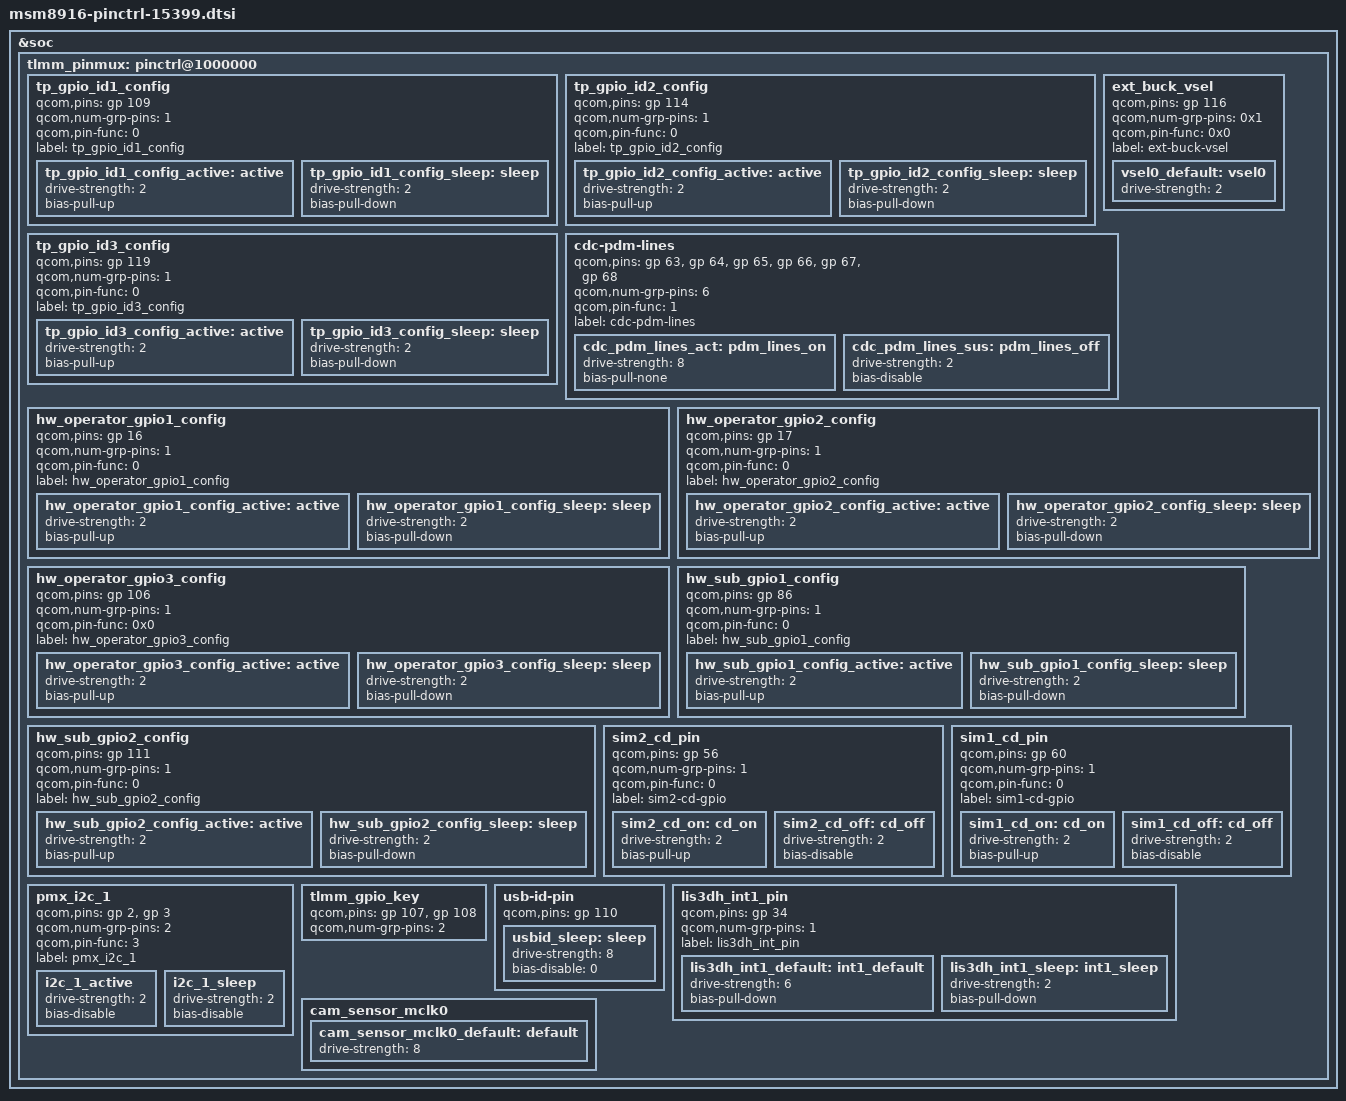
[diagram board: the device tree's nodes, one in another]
/* Copyright (c) 2020, The Linux Foundation. All rights reserved.
*  Copyright (c) 2020, the_shahnawaz_sheikh (sheikhshahnawaz41299).
*
* This program is free software; you can redistribute it and/or modify
* it under the terms of the GNU General Public License version 2 and
* only version 2 as published by the Free Software Foundation.
*
* This program is distributed in the hope that it will be useful,
* but WITHOUT ANY WARRANTY; without even the implied warranty of
* MERCHANTABILITY or FITNESS FOR A PARTICULAR PURPOSE.  See the
* GNU General Public License for more details.
*/

#include "../msm8916-pinctrl.dtsi"

&soc {
	tlmm_pinmux: pinctrl@1000000 {
	
	    /delete-node/ tps61310_pins;
		/delete-node/ spi2_cs2_active;
		/delete-node/ spi2_cs2_suspend;
		/delete-node/ spi2_active;
		/delete-node/ spi2_suspend;
		/delete-node/ ice40-spi-usb-pins;
		
		tp_gpio_id1_config {
			qcom,pins = <&gp 109>;
			qcom,num-grp-pins = <1>;
			qcom,pin-func = <0>;
			label = "tp_gpio_id1_config";

			tp_gpio_id1_config_active: active {
				drive-strength = <2>;
				bias-pull-up;
			};

			tp_gpio_id1_config_sleep: sleep {
				drive-strength = <2>;
				bias-pull-down;
			};
		};

		tp_gpio_id2_config {
			qcom,pins = <&gp 114>;
			qcom,num-grp-pins = <1>;
			qcom,pin-func = <0>;
			label = "tp_gpio_id2_config";

			tp_gpio_id2_config_active: active {
				drive-strength = <2>;
				bias-pull-up;
			};

			tp_gpio_id2_config_sleep: sleep {
				drive-strength = <2>;
				bias-pull-down;
			};
		};
		
		tp_gpio_id3_config { 
			qcom,pins = <&gp 119>;
			qcom,num-grp-pins = <1>;
			qcom,pin-func = <0>;
			label = "tp_gpio_id3_config";

			tp_gpio_id3_config_active:	active {
					drive-strength = <2>;
					bias-pull-up;
			};

			tp_gpio_id3_config_sleep:	sleep {
					drive-strength = <2>;
					bias-pull-down;
			};
		};
		
		ext_buck_vsel { 
			qcom,pins = <&gp 116>;
			qcom,num-grp-pins = <0x1>;
			qcom,pin-func = <0x0>;
			label = "ext-buck-vsel";

			vsel0_default: vsel0 {
					drive-strength = <2>;
			};
		};
		
		cdc-pdm-lines {
			 qcom,pins = <&gp 63>, <&gp 64>, <&gp 65>,
					<&gp 66>, <&gp 67>, <&gp 68>;
			 qcom,num-grp-pins = <6>;
			 qcom,pin-func = <1>;
			 label = "cdc-pdm-lines";
			 
			 cdc_pdm_lines_act: pdm_lines_on {
				  drive-strength = <8>;
				  bias-pull-none;
			 };
			  
			 cdc_pdm_lines_sus: pdm_lines_off {
				  drive-strength = <2>;
				 /delete-property/ bias-pull-down; 
				 bias-disable;  
			 };
	    };
		
		hw_operator_gpio1_config { 
				qcom,pins = <&gp 16>;
				qcom,num-grp-pins = <1>;
				qcom,pin-func = <0>;
				label = "hw_operator_gpio1_config";

			hw_operator_gpio1_config_active: active {
					drive-strength = <2>;
					bias-pull-up;
				};

			hw_operator_gpio1_config_sleep:	sleep {
					drive-strength = <2>;
					bias-pull-down;
				};
		};

		hw_operator_gpio2_config { 
				qcom,pins = <&gp 17>;
				qcom,num-grp-pins = <1>;
				qcom,pin-func = <0>;
				label = "hw_operator_gpio2_config";

			hw_operator_gpio2_config_active:	active {
					drive-strength = <2>;
					bias-pull-up;
				};

			hw_operator_gpio2_config_sleep:	sleep {
					drive-strength = <2>;
					bias-pull-down;
				};
		};

		hw_operator_gpio3_config { 
				qcom,pins = <&gp 106>;
				qcom,num-grp-pins = <1>;
				qcom,pin-func = <0x0>;
				label = "hw_operator_gpio3_config";

			hw_operator_gpio3_config_active:	active {
					drive-strength = <2>;
					bias-pull-up;
				};

			hw_operator_gpio3_config_sleep:	sleep {
					drive-strength = <2>;
					bias-pull-down;
				};
		};


		hw_sub_gpio1_config {
			qcom,pins = <&gp 86>;
			qcom,num-grp-pins = <1>;
			qcom,pin-func = <0>;
			label = "hw_sub_gpio1_config";

			hw_sub_gpio1_config_active: active {
				drive-strength = <2>;
				bias-pull-up;
			};

			hw_sub_gpio1_config_sleep: sleep {
				drive-strength = <2>;
				bias-pull-down;
			};
		};

		hw_sub_gpio2_config {
			qcom,pins = <&gp 111>;
			qcom,num-grp-pins = <1>;
			qcom,pin-func = <0>;
			label = "hw_sub_gpio2_config";

			hw_sub_gpio2_config_active: active {
				drive-strength = <2>;
				bias-pull-up;
			};

			hw_sub_gpio2_config_sleep: sleep {
				drive-strength = <2>;
				bias-pull-down;
			};
		};

		sim2_cd_pin {
			qcom,pins = <&gp 56>;
			qcom,num-grp-pins = <1>;
			qcom,pin-func = <0>;
			label = "sim2-cd-gpio";

			sim2_cd_on: cd_on {
				drive-strength = <2>;
				bias-pull-up;
			};

			sim2_cd_off: cd_off {
				drive-strength = <2>;
				bias-disable;
			};
		};

		sim1_cd_pin {
			qcom,pins = <&gp 60>;
			qcom,num-grp-pins = <1>;
			qcom,pin-func = <0>;
			label = "sim1-cd-gpio";

			sim1_cd_on: cd_on {
				drive-strength = <2>;
				bias-pull-up;
			};

			sim1_cd_off: cd_off {
				drive-strength = <2>;
				bias-disable;
			};
		};

		pmx_i2c_1 {
			qcom,pins = <&gp 2>, <&gp 3>;
			qcom,num-grp-pins = <2>;
			qcom,pin-func = <3>;
			label = "pmx_i2c_1";

			i2c_1_active: i2c_1_active {
				drive-strength = <2>;
				bias-disable;
			};

			i2c_1_sleep: i2c_1_sleep {
				drive-strength = <2>;
				bias-disable;
			};
		};
		
		
		tlmm_gpio_key {
              qcom,pins = <&gp 107> , <&gp 108>;
              qcom,num-grp-pins = <2>;
         };

		usb-id-pin {
			qcom,pins = <&gp 110>;

			usbid_sleep: sleep {
				drive-strength = <8>;
				bias-disable = <0>;
			};
		};

		lis3dh_int1_pin {
			qcom,pins = <&gp 34>;
			qcom,num-grp-pins = <1>;
			label = "lis3dh_int_pin";

			lis3dh_int1_default: int1_default {
				drive-strength = <6>;
				bias-pull-down;
			};

			lis3dh_int1_sleep: int1_sleep {
				drive-strength = <2>;
				bias-pull-down;
			};
		};
		
		cam_sensor_mclk0 {
			cam_sensor_mclk0_default: default {
				drive-strength = <8>; /* 8 MA */
			};
		};
		
	};
};


